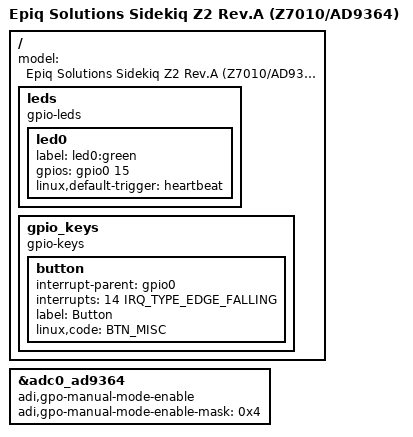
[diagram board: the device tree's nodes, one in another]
/dts-v1/;
/include/ "zynq-pluto-sdr.dtsi"
#include <dt-bindings/input/input.h>
#include <dt-bindings/gpio/gpio.h>
#include <dt-bindings/interrupt-controller/irq.h>

/ {
	model = "Epiq Solutions Sidekiq Z2 Rev.A (Z7010/AD9364)";

	leds {
		compatible = "gpio-leds";
		led0 {
			label = "led0:green";
			gpios = <&gpio0 15 0>;
			linux,default-trigger = "heartbeat";
		};
	};

	gpio_keys {
		compatible = "gpio-keys";
		#address-cells = <1>;
		#size-cells = <0>;

		button {
			interrupt-parent = <&gpio0>;
			interrupts = <14 IRQ_TYPE_EDGE_FALLING>;
			label = "Button";
			linux,code = <BTN_MISC>;
		};

	};
};

&adc0_ad9364 {
	adi,gpo-manual-mode-enable;
	adi,gpo-manual-mode-enable-mask = <0x4>;
};
